VERSION ""

NS_ :

BS_:

BU_: RetrofitKit ANM

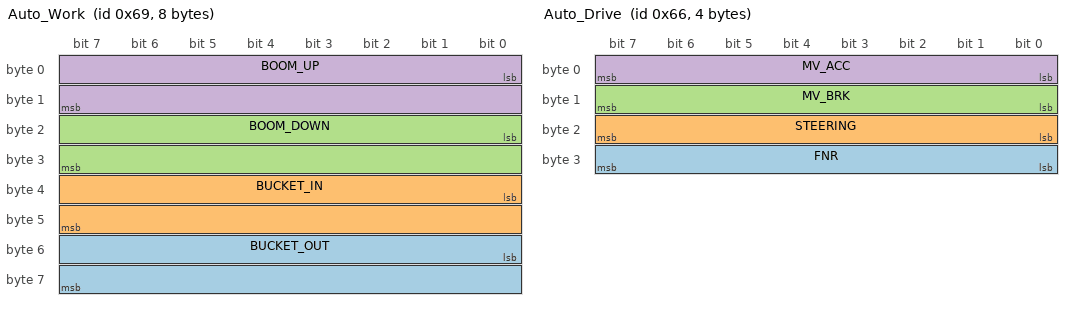
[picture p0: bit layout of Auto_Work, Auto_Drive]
BO_ 105 Auto_Work: 8 ANM
 SG_ BUCKET_OUT : 48|16@1+ (0.1,0) [0|100] ""  RetrofitKit
 SG_ BUCKET_IN : 32|16@1+ (0.1,0) [0|100] ""  RetrofitKit
 SG_ BOOM_DOWN : 16|16@1+ (0.1,0) [0|100] ""  RetrofitKit
 SG_ BOOM_UP : 0|16@1+ (0.1,0) [0|100] ""  RetrofitKit

BO_ 102 Auto_Drive: 4 ANM
 SG_ FNR : 24|8@1+ (1,0) [0|0] ""  RetrofitKit
 SG_ STEERING : 16|8@1- (1,0) [-100|100] "%"  RetrofitKit
 SG_ MV_BRK : 8|8@1+ (1,0) [0|100] "%"  RetrofitKit
 SG_ MV_ACC : 0|8@1+ (1,0) [0|100] "%"  RetrofitKit

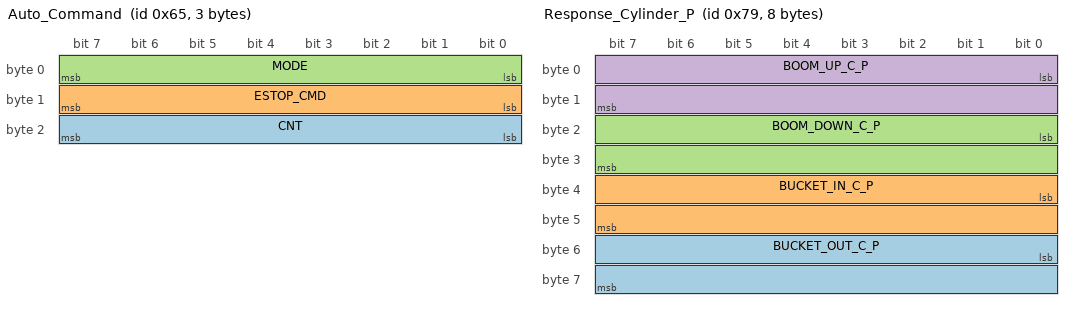
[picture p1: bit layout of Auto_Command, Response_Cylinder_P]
BO_ 101 Auto_Command: 3 ANM
 SG_ CNT : 16|8@1+ (1,0) [0|255] ""  RetrofitKit
 SG_ ESTOP_CMD : 8|8@1+ (1,0) [0|0] ""  RetrofitKit
 SG_ MODE : 0|8@1+ (1,0) [0|0] ""  RetrofitKit

BO_ 121 Response_Cylinder_P: 8 RetrofitKit
 SG_ BUCKET_OUT_C_P : 48|16@1+ (0.1,0) [0|200] "bar"  ANM
 SG_ BUCKET_IN_C_P : 32|16@1+ (0.1,0) [0|200] "bar"  ANM
 SG_ BOOM_DOWN_C_P : 16|16@1+ (0.1,0) [0|200] "bar"  ANM
 SG_ BOOM_UP_C_P : 0|16@1+ (0.1,0) [0|200] "bar"  ANM

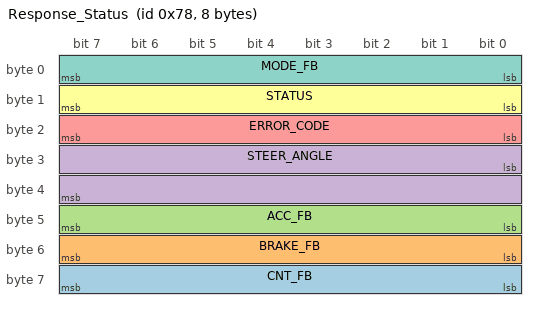
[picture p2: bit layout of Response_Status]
BO_ 120 Response_Status: 8 RetrofitKit
 SG_ CNT_FB : 56|8@1+ (1,0) [0|255] ""  ANM
 SG_ BRAKE_FB : 48|8@1+ (1,0) [0|0] "%"  ANM
 SG_ ACC_FB : 40|8@1+ (1,0) [0|0] "%"  ANM
 SG_ STEER_ANGLE : 24|16@1- (0.1,0) [-180|180] "degree"  ANM
 SG_ ERROR_CODE : 16|8@1+ (1,0) [0|0] ""  ANM
 SG_ STATUS : 8|8@1+ (1,0) [0|0] ""  ANM
 SG_ MODE_FB : 0|8@1+ (1,0) [0|0] ""  ANM

CM_ SG_ 101 CNT "alive counter

";
CM_ SG_ 101 ESTOP_CMD "0: Nothing 1: E-Stop
";
CM_ SG_ 101 MODE "0: Auto mode OFF, 1: Auto mode ON
";
CM_ SG_ 120 STATUS "0: Error, 1: Ready, 2: Moving, 3: E-Stop
";
CM_ SG_ 120 MODE_FB "0: Manual, 1: Remote, 2: Auto
";
BA_DEF_  "BusType" STRING ;
BA_DEF_DEF_  "BusType" "CAN";
